# S32R372 register map
Vendor: Freescale Semiconductor, Inc.; Series: Qorivva; File version: 1.6
Registers are 32-bit, read-write, reset 0x0 unless marked. A register's access mark holds for its fields unless they carry their own. Offsets are from the block's base; [hi:lo] are bit positions; {n}, {i} and the like mark numbered series.

## FCCU
Base 0xFBF58000; register names take the prefix FCCU_
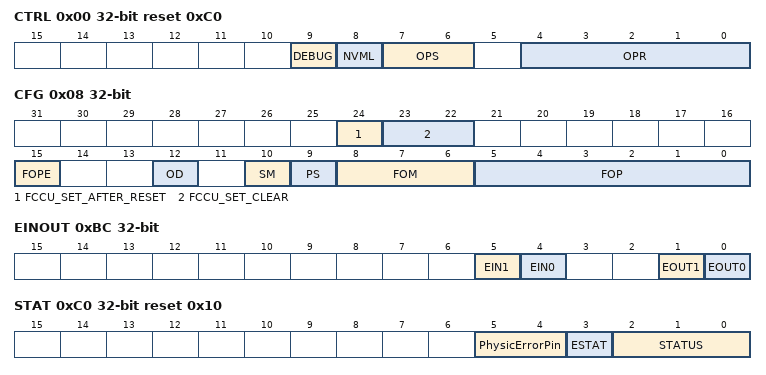
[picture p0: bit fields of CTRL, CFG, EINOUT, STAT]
0x00 CTRL reset 0xC0 — Control
  [9] DEBUG — Debug Mode Enable
    0=Disabled; 1=Enabled
  [8] NVML ro — Nonvolatile Memory Configuration Loaded
    0=Not loaded; 1=Loaded
  [7:6] OPS ro — Operation status. This bit can be read and cleared (via OP15 operation) by the software.
    0=Idle; 1=In progress; 2=Aborted; 3=Successful
  [4:0] OPR — Operation Run
0x04 CTRLK wo — Control Key
  [31:0] CTRLK — Locked-Operation Control Key
0x08 CFG reset not defined — Configuration
  [24] FCCU_SET_AFTER_RESET — Fault-Output (EOUT) Activate
    0=Inactive (the EOUT signals are in a high-impedance state); 1=Active (the EOUT signals indicate FCCU's condition)
  [23:22] FCCU_SET_CLEAR — Fault-Output (EOUT) Control
    0=Controlled by the FSM; 1=Always low; 2=Controlled by the FSM; 3=High until a fault occurs on a channel, regardless of whether that fault is disabled; thereafter, controlled by the FSM. Note: FCCU ignores an attempt to write this value if the fault-output (EOUT) timer is already running.
  [15] FOPE — Fault-Output (EOUT) Prescaler Extension
  [12] OD — Open-Drain Mechanism to select between Push-pull and Open drain(OD) mode for the error indicating pin(s)
    0=Push-pull; 1=Open-drain
  [10] SM — Fault-Output (EOUT) Switching Mode
    0=Slow: No EOUT frequency violation during the FCCU state transition (Normal to Fault or vice versa, and Configuration to Normal). The indication transition occurs after a maximum delay equal to the duration of the semiperiod of the EOUT frequency.; 1=Fast: The indication transition (Normal to Fault or vice versa, and Configuration to Normal) occurs immediately. A pulse with the minimum duration corresponding to the CLKSAFE period can occur in this mode. It implies a frequency violation of the EOUT protocol.
  [9] PS — Fault-Output (EOUT) Polarity Selection
    0=For the faulty indication, EOUT1 is high, and EOUT0 is low; 1=For the faulty indication, EOUT1 is low, and EOUT0 is high
  [8:6] FOM — Fault-Output (EOUT) Mode
    0=Dual-Rail (default state) [EOUT[1:0]= outputs]; 1=Time-Switching [EOUT[1:0]= output to be used]; 2=Bistable; 5=Test 0 (controlled by the FCCU_EINOUT register; EOUT1 is an output; EOUT0 is an input); 6=Test 1 (controlled by the FCCU_EINOUT register; EOUT1 and EOUT0 are both outputs); 7=Test 2 (controlled by the FCCU_EINOUT register; EOUT1 is an input; EOUT0 is an output)
  [5:0] FOP — Fault-Output (EOUT) Prescaler
{0x1C+4i} NCF_CFG{i} (i=0..3) reset not defined — Noncritical Fault Configuration
  [31:0] NCFCx
    0=Hardware-recoverable fault; 1=Software-recoverable fault
{0x4C+4i} NCFS_CFG{i} (i=0..7) reset not defined — Noncritical Fault State Configuration
  [31:0] NCFSCx — Noncritical fault state configuration See for register offset to channel number relationship.
    0=No reset reaction; 1=Short functional reset request pulse (FAULT state reaction); 2=Long functional reset request pulse (FAULT state reaction); 3=No reset reaction
{0x80+4i} NCF_S{i} (i=0..3) — Noncritical Fault Status
  [31:0] NCFSx — Noncritical fault status
    0=No "noncritical" fault latched; 1="Noncritical" fault latched
0x90 NCFK wo — Noncritical Fault Key
  [31:0] NCFK — Noncritical fault key = AB34_98FEh
{0x94+4i} NCF_E{i} (i=0..3) reset not defined — Noncritical Fault Enable
  [31:0] NCFEx — Noncritical fault enable For the mapping of the NCFEx fields among registers, see the earlier table in this register description
    0=No actions following the respective noncritical fault assertion; 1=FCCU moves to ALARM or FAULT state
{0xA4+4i} NCF_TOE{i} (i=0..3) reset not defined — Noncritical Fault Timeout Enable
  [31:0] NCFTOEx — Fault timeout enable For the mapping of the NCFTOEx fields among registers, see the earlier table in this register description
    0=FCCU moves into the FAULT state if the respective fault is enabled; 1=FCCU moves into the ALARM state if the respective fault is enabled
0xB4 NCF_TO reset not defined — Noncritical Fault Timeout
  [31:0] TO — Noncritical Fault Timeout Timeout = (TO) * T RC16MHz
0xB8 CFG_TO reset not defined — Configuration-State Timer Interval
  [2:0] TO
0xBC EINOUT (reset mask 0xFFFFFFCF) — IO Control
  [5] EIN1 ro — Error Input 1
    0=Low; 1=High
  [4] EIN0 ro — Error Input 0
    0=Low; 1=High
  [1] EOUT1 — Error out 1 (significant only if the FCCU_CFG
    0=force EOUT[1] = 0; 1=force EOUT[1] = 1
  [0] EOUT0 — Error out 0 (significative only if the FCCU_CFG
    0=force EOUT[0] = 0; 1=force EOUT[0] = 1
0xC0 STAT ro reset 0x10 — Status
  [5:4] PhysicErrorPin — Fault Output (EOUT) States
    0=EOUT1 is low; EOUT0 is low; 1=EOUT1 is low; EOUT0 is high; 2=EOUT1 is high; EOUT0 is low; 3=EOUT1 is high; EOUT0 is high
  [3] ESTAT — Fault State
    0=Not in Fault state (in Normal, Alarm, or Configuration state); 1=In Fault state
  [2:0] STATUS — FCCU State
    0=Normal; 1=Configuration; 2=Alarm; 3=Fault
0xC4 N2AF_STATUS ro — NA Freeze Status
  [7:0] NAFS — Normal to Alarm Frozen Status 00000000 No transition from NORMAL to ALARM state 00000001 NORMAL to ALARM state transition cause => fccu_ncf[0] fault 00000010 NORMAL to ALARM state transition cause => fccu_ncf[1] fault 00000011 NORMAL to ALARM state transition cause => fccu_ncf[2] fault
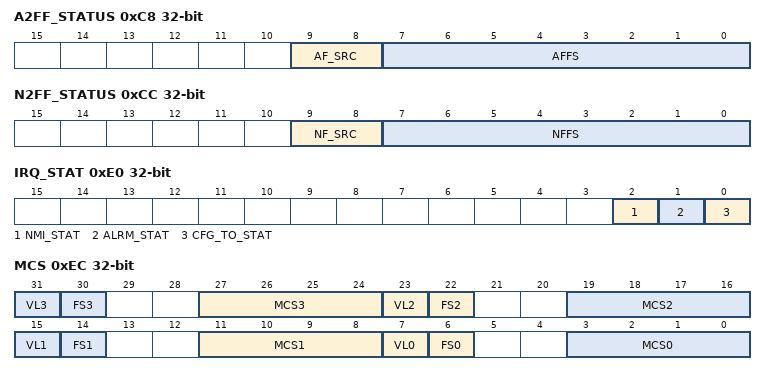
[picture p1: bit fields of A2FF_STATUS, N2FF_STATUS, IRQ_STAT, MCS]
0xC8 A2FF_STATUS ro — AF Freeze Status
  [9:8] AF_SRC — Fault source
    0=No fault; 2="Noncritical" fault; 3=Multiple and/or "noncritical" faults
  [7:0] AFFS — Alarm to Fault Frozen Status 00h: No transition from ALARM to FAULT state 01h: ALARM to FAULT state transition cause => fccu_ncf[0]/ fault timeout fault 02h: ALARM to FAULT state transition cause => fccu_ncf[1]/ fault timeout fault 03h: ALARM to FAULT state transition cause => fccu_ncf[2]/ fault timeout fault
0xCC N2FF_STATUS ro — NF Freeze Status
  [9:8] NF_SRC — NF_SRC: Fault source
    0=No fault; 2="Noncritical" fault; 3=Multiple "noncritical" faults
  [7:0] NFFS — Normal to Fault Frozen Status 00h: No transition from NORMAL to FAULT state 01h: NORMAL to FAULT state transition cause => fccu_ncf[0] fault 02h: NORMAL to FAULT state transition cause => fccu_ncf[1] fault 03h: NORMAL to FAULT state transition cause => fccu_ncf[2] fault
0xD0 F2A_STATUS ro — FA Freeze Status
  [8:0] FAFS — Fault to Normal Frozen Status 00h: No transition from FAULT to ALARM state 01h: FAULT to ALARM state transition cause => fccu_ncf[0]/ fault 02h: FAULT to ALARM state transition cause => fccu_ncf[1]/ fault 03h: FAULT to ALARM state transition cause => fccu_ncf[2]/ fault
0xDC NCFF — Noncritical Fault Fake
  [6:0] FNCFC wo — FNCFC/ : Fake noncritical fault code Only writing to this register, fake fault injection occurs, writing 00 and default value being zero give different results
0xE0 IRQ_STAT — IRQ Status
  [2] NMI_STAT ro — NMI Interrupt Status
    0=NMI interrupt is OFF; 1=NMI interrupt is ON
  [1] ALRM_STAT ro — Alarm Interrupt Status
    0=Alarm interrupt is OFF; 1=Alarm interrupt is ON
  [0] CFG_TO_STAT — Configuration Timeout Status
    0=No configuration timeout error; 1=Configuration timeout error
0xE4 IRQ_EN — IRQ Enable
  [0] CFG_TO_IEN — Configuration Timeout Interrupt Enable
    0=Configuration timeout interrupt disabled; 1=Configuration timeout interrupt enabled
0xE8 XTMR ro
  [31:0] XTMR — Alarm/Watchdog The current timer value is measured in CLKSAFE cycles
0xEC MCS ro — Mode Controller Status
  [8n+7] VL{n} (n=0..3) — Valid {n}-Indicates whether MCS{n} and FS{n} are valid.
    0=Invalid; 1=Valid
  [8n+6] FS{n} (n=0..3) — Fault Status {n}
    0=Not in Fault state or NMIOUT not asserted; 1=In Fault state and NMIOUT asserted
  [27:24] MCS3 — Mode Controller State 3-Indicates the fourth most recent chip mode.
  [19:16] MCS2 — Mode Controller State 2-Indicates the third most recent chip mode.
  [11:8] MCS1 — Mode Controller State 1-Indicates the second most recent chip mode.
  [3:0] MCS0 — Mode Controller State 0-Indicates the most recent (current) chip mode.
0xF0 TRANS_LOCK — Transient Configuration Lock
  [8:0] TRANSKEY wo
0xF4 PERMNT_LOCK — Permanent Configuration Lock
  [8:0] PERMNTKEY wo
0xF8 DELTA_T
  [13:0] DELTA_T — Bistable Minimum Fault-Output (EOUT) Faulty Interval
{0xFC+4i} IRQ_ALARM_EN{i} (i=0..3) — IRQ Alarm Enable
  [31:0] IRQENx — IRQ alarm enable For the mapping of the IRQENx fields among registers, see the earlier table in this register description
    0=Alarm is disabled for error source x; 1=Alarm is enabled for error source x
{0x10C+4i} NMI_EN{i} (i=0..3) — NMI Enable
  [31:0] NMIENx — NMI enable See for register offset to channel number relationship.
    0=NMI is disabled for error (NCF) source x; 1=NMI is enabled for error (NCF) source x
{0x11C+4i} EOUT_SIG_EN{i} (i=0..3) — Bistable Fault-Output (EOUT) Mode Signaling Enable
  [31:0] EOUTENx — Bistable Fault-Output (EOUT) Mode Signaling Enable x
    0=Disabled; 1=Enabled
